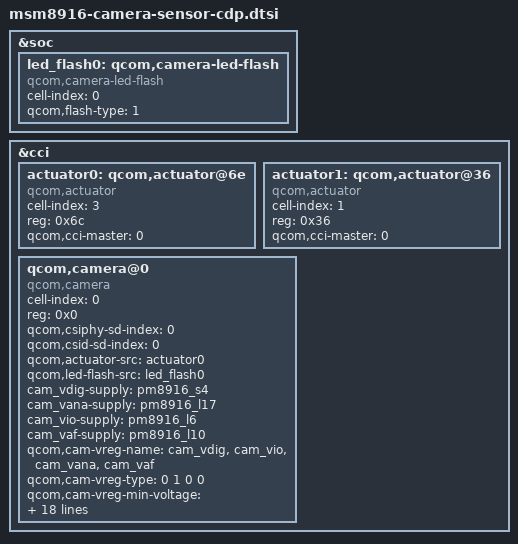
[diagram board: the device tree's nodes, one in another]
/*
 * Copyright (c) 2014, The Linux Foundation. All rights reserved.
 *
 * This program is free software; you can redistribute it and/or modify
 * it under the terms of the GNU General Public License version 2 and
 * only version 2 as published by the Free Software Foundation.
 *
 * This program is distributed in the hope that it will be useful,
 * but WITHOUT ANY WARRANTY; without even the implied warranty of
 * MERCHANTABILITY or FITNESS FOR A PARTICULAR PURPOSE.  See the
 * GNU General Public License for more details.
 */

&soc {

	led_flash0: qcom,camera-led-flash {
		cell-index = <0>;
		compatible = "qcom,camera-led-flash";
		qcom,flash-type = <1>;
	};
};

&cci {

	actuator0: qcom,actuator@6e {
		cell-index = <3>;
		reg = <0x6c>;
		compatible = "qcom,actuator";
		qcom,cci-master = <0>;
	};

	actuator1: qcom,actuator@36 {
		cell-index = <1>;
		reg = <0x36>;
		compatible = "qcom,actuator";
		qcom,cci-master = <0>;
	};


	qcom,camera@0 {
		cell-index = <0>;
		compatible = "qcom,camera";
		reg = <0x0>;
		qcom,csiphy-sd-index = <0>;
		qcom,csid-sd-index = <0>;
		qcom,actuator-src = <&actuator0>;
		qcom,led-flash-src = <&led_flash0>;
        cam_vdig-supply = <&pm8916_s4>;
        cam_vana-supply = <&pm8916_l17>;
        cam_vio-supply = <&pm8916_l6>;
        cam_vaf-supply = <&pm8916_l10>;
		qcom,cam-vreg-name = "cam_vdig", "cam_vio", "cam_vana",
				     "cam_vaf";
		qcom,cam-vreg-type = <0 1 0 0>;
		qcom,cam-vreg-min-voltage = <2100000 0 2850000 2800000>;
		qcom,cam-vreg-max-voltage = <2100000 0 2850000 2800000>;
		qcom,cam-vreg-op-mode = <200000 0 80000 100000>;
		pinctrl-names = "cam_default", "cam_suspend";
		pinctrl-0 = <&cam_sensor_rear_mclk_default &cam_sensor_rear_default>;
		pinctrl-1 = <&cam_sensor_rear_mclk_sleep &cam_sensor_rear_sleep>;
		gpios = <&msmgpio 26 0>,
	        <&msm_gpio 35 0>,
	        <&msm_gpio 34 0>;
		qcom,gpio-reset = <1>;
		qcom,gpio-standby = <2>;
		qcom,gpio-req-tbl-num = <0 1 2>;
		qcom,gpio-req-tbl-flags = <1 0 0>;
		qcom,gpio-req-tbl-label = "CAMIF_MCLK",
			"CAM_RESET1",
			"CAM_STANDBY";
		qcom,cci-master = <0>;
		status = "ok";
		clocks = <&clock_gcc clk_mclk0_clk_src>,
			     <&clock_gcc clk_gcc_camss_mclk0_clk>;
		clock-names = "cam_src_clk", "cam_clk";
	};
};
